# EOS-S3 register map
File version: 0.1
CPU: CM4 r0p1, selectable endian, MPU, FPU, 3 interrupt priority bits
Registers are 32-bit, read-write, reset 0x0 unless marked. A register's access mark holds for its fields unless they carry their own. Offsets are from the block's base; lines under a group give offsets from that group; [hi:lo] are bit positions; {n}, {i} and the like mark numbered series; 'fields as' and 'values as' point back to an identical list; <NAME> marks a mode.

## Memory map
0x40000000 EXTM4Regs size 0x304 — External registers to control M4 Subsystem (not a core peripheral)
0x40002000 PKFB size 0x58 — Packet FFO Bank control
0x40002000 PMU size 0x3FC — Power Management Unit
0x40004000 CRU size 0x148 — Clock Reset Unit
0x40004800 INTR_CTRL size 0xA8 — Interrupt Controller
0x40004C00 IOMUX size 0x1B0 — IO Multiplexing Control
0x40005000 MISC size 0x400 — MISC registers
0x40005400 AIP size 0x218 — Analog IP block
0x40005A00 ADC size 0xC — Analog-to-Digital Converter
0x40005C00 SPT size 0x40 — Simple Periodic Timer
0x40006000 A1_Regs size 0x4 — Selects source APB Master to SPI Master between M4/AP and Fabric
0x40007000 SPI size 0x64 — SPI peripheral control
0x40007400 DMA size 0x1C — Direct Memory Access peripheral
0x4000B000 I2S_Slave size 0x3FC
0x4000C000 SDMA size 0x1000 — System Direct Access Memory
0x4000D000 SDMA_Bridge size 0x14 — System Direct Memory Access Bridge
0x4000F000 SDMA_SRAM size 0x1FC — System DMA SRAM
0x40010000 UART size 0x1000 — Universal Asynchronous Receiver Transmitter
0x40012000 WDT size 0x1000 — WatchDog Timer
0x40013000 TIMER size 0x1000 — Timer peripheral
0x40014000 CFG_CTL size 0xB000 — PIF Register (FPGA Programming interface)
0x40015000 AUD size 0x34 — Audio Subsystem
0x4004A000 ExtRegsFFE size 0x170 — Flexible Fusion Engine registers
0x40050000 SPI_TLC size 0x80 — Communication Manager - Top Level controller
0xE000E008 SCB_ACTRL size 0x5 — System control block ACTLR
0xE000E100 NVIC size 0x356 — Nested Vectored Interrupt Controller

## Interrupts
0 Software_Interrupt_2 (INTR_CTRL)
1 Software_Interrupt_1 (INTR_CTRL)
3 FFE0_Message (INTR_CTRL)
4 Fabric_Message (INTR_CTRL)
5 Sensor_GPIO (INTR_CTRL) — Global GPIO interrupt
7 UART (INTR_CTRL) — Global UART interrupt
8 TIMER (INTR_CTRL) — Interrupt triggered when a timer counts down to 0. The status can be read and cleared (0x4000_4830[2]), and can be masked (0x4000_4834[2] for Host), and (0x4000_4838[2] for M4).
9 CPU_WDOG_INTR (INTR_CTRL)
10 CPU_WDOG_RST (INTR_CTRL)
11 BUS_Timeout (INTR_CTRL)
12 FPU (INTR_CTRL)
13 PKFB (INTR_CTRL)
14 I2S (INTR_CTRL)
15 Audio (INTR_CTRL)
16 SPI_MS (INTR_CTRL)
17 CFG_DMA (INTR_CTRL)
18 PMU_TIMER (INTR_CTRL)
19 ADC_DONE (INTR_CTRL) — ADC Done interrupt
20 RTC_Alarm (INTR_CTRL)
21 Reset_Interrupt (INTR_CTRL)
22 FFE0_Combined (INTR_CTRL)
23 FFE_WDT (INTR_CTRL)
24 AP_Boot (INTR_CTRL)
25 LDO30_PG_INTR (INTR_CTRL)
26 LDO50_PG_INTR (INTR_CTRL)
27 SRAM_128_TIMEOUT (INTR_CTRL)
28 LPSD_Voice_Det (INTR_CTRL)
29 DMIC_Voice_Det (INTR_CTRL)
{n+30} SDMA_DONE_{n} (INTR_CTRL) (n=1..11)
42 AP_PDM_CLK_ON (INTR_CTRL)
43 AP_PDM_CLK_OFF (INTR_CTRL)
44 DMAC0_BLK_DONE (INTR_CTRL)
45 DMAC0_BUF_DONE (INTR_CTRL)
46 DMAC1_BLK_DONE (INTR_CTRL)
47 DMAC1_BUF_DONE (INTR_CTRL)
48 SDMA_DONE_0 (INTR_CTRL)
49 SDMA_ERR (INTR_CTRL)
50 I2SSLV_M4_tx_or_intr (INTR_CTRL)
51 LPSD_VOICE_OFF (INTR_CTRL)
52 DMIC_VOICE_OFF (INTR_CTRL)

## NVIC — Nested Vectored Interrupt Controller
Base 0xE000E100
{0x0+4i} ISER{i} (i=0..2) — Interrupt Set-Enable Register
  [31:0] SETENA
{0x80+4i} ICER{i} (i=0..2) — Interrupt Clear-Enable Register
  [31:0] CLRENA
{0x100+4i} ISPR{i} (i=0..2) — Interrupt Set-Pending Register
  [31:0] SETPEND
{0x180+4i} ICPR{i} (i=0..2) — Interrupt Clear-Pending Register
  [31:0] CLRPEND
{0x200+4i} IABR{i} ro (i=0..2) — Interrupt Active Bit Register
  [31:0] ACTIVE
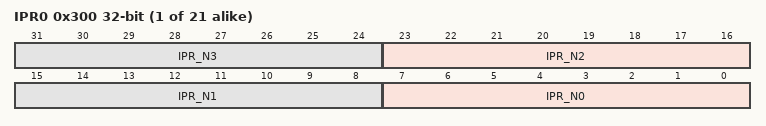
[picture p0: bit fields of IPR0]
{0x300+4i} IPR{i} (i=0..20) — Interrupt Priority Register
  [8n+7:8n] IPR_N{n} (n=0..3)

## A1_Regs — Selects source APB Master to SPI Master between M4/AP and Fabric
Base 0x40006000
0x00 CFG_CTRL — Configuration Control
  [0] CFG_IN_SEL — Selects source APB master to SPI Master between M4/AP and Fabric
